# SAMA7G54D4G device description
Architecture: CORTEX-A7; Family: SAMA; Series: SAMA7G
Registers are 32-bit, read-write, reset 0x0 unless marked. A register's access mark holds for its fields unless they carry their own. Offsets are from the block's base; [hi:lo] are bit positions; {n}, {i} and the like mark numbered series.

## DDR3PHY — DDR SDRAM PHY Utility Block Lite
Instances: DDRPUBL 0xE3804000
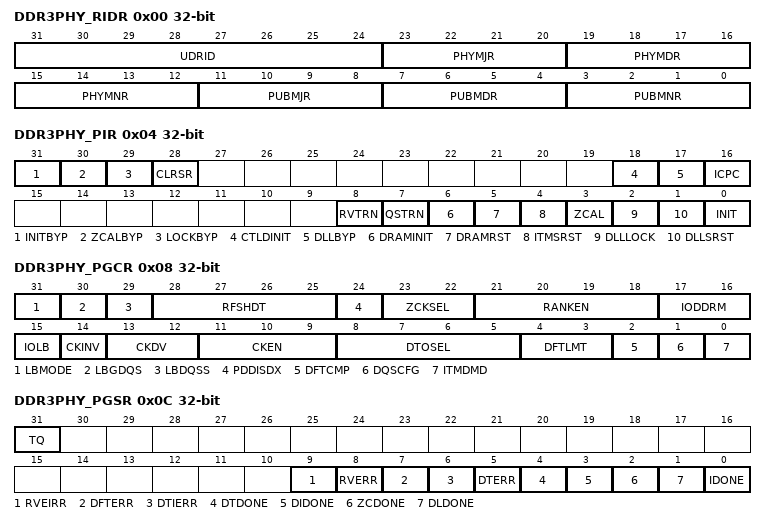
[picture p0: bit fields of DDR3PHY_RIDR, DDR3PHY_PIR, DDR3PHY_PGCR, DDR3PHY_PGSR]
0x00 DDR3PHY_RIDR ro reset not defined — Revision Identification Register
  [31:24] UDRID — User-Defined Revision ID: General purpose revision identification set by the user.
  [23:20] PHYMJR — PHY Major Revision: Indicates major revision of the PHY such addition of the features that make the new version not compatible with previous versions.
  [19:16] PHYMDR — PHY Moderate Revision: Indicates moderate revision of the PHY such as addition of new features. Normally the new version is still compatible with previous versions.
  [15:12] PHYMNR — PHY Minor Revision: Indicates minor update of the PHY such as bug fixes. Normally no new features are included.
  [11:8] PUBMJR — PUB Major Revision: Indicates major revision of the PUB such addition of the features that make the new version not compatible with previous versions.
  [7:4] PUBMDR — PUB Moderate Revision: Indicates moderate revision of the PUB such as addition of new features. Normally the new version is still compatible with previous versions.
  [3:0] PUBMNR — PUB Minor Revision: Indicates minor update of the PUB such as bug fixes. Normally no new features are included.
0x04 DDR3PHY_PIR reset not defined — PHY Initialization Register
  [31] INITBYP — Initialization Bypass: Bypasses or stops, if set, all initialization routines currently running, including PHY initialization, DRAM initialization, and PHY training.
  [30] ZCALBYP — Impedance Calibration Bypass: Bypasses or stops, if set, impedance calibration of all ZQ control blocks that automatically triggers after reset. Impedance calibration may be triggered manually using INIT and ZCAL bits of the PIR register. This bit is self-clearing.
  [29] LOCKBYP — DLL Lock Bypass: Bypasses or stops, if set, the waiting of DLLs to lock. DLL lock wait is automatically triggers after reset. DLL lock wait may be triggered manually using INIT and DLLLOCK bits of the PIR register. This bit is self-clearing.
  [28] CLRSR — Clear Status Registers
  [18] CTLDINIT — Controller DRAM Initialization: Indicates if set that DRAM initialization will be performed by the controller. Otherwise if not set it indicates that DRAM initialization will be performed using the built-in initialization sequence or using software through the configuration port.
  [17] DLLBYP — DLL Bypass: A setting of 1 on this bit will put all PHY DLLs in bypass mode. A bypassed DLL is also powered down (disabled).
  [16] ICPC — Initialization Complete Pin Configuration: Specifies how the DFI 2.1 initialization complete output pin should be used to indicate the status of initialization.
  [8] RVTRN — Read DQS gate training (QSTRN) and RV training (RVTRN) should normally be run together. It is expected RVTRN is normally be set whenever PIR.QSTRN is set.
  [7] QSTRN — Read DQS Training: Executes a PUBL training routine to determine the optimum position of the read data DQS strobe for maximum system timing margins.
  [6] DRAMINIT — DRAM Initialization: Executes the DRAM initialization sequence.
  [5] DRAMRST — DRAM Reset (DDR3 Only): Issues a reset to the DRAM (by driving the DRAM reset pin low) and wait 200us. This can be triggered in isolation or with the full DRAM initialization (DRAMINIT). For the latter case, the reset is issued and 200us is waited before starting the full initialization sequence.
  [4] ITMSRST — Interface Timing Module Soft Reset: Soft resets the interface timing modules for the data and data strobes, i.e., it asserts the ITM soft reset (srstb) signal.
  [3] ZCAL — Impedance Calibrate: Performs PHY impedance calibration.
  [2] DLLLOCK — DLL Lock: Waits for the PHY DLLs to lock.
  [1] DLLSRST — DLL Soft Rest: Soft resets all PHY DLLs by driving the DLL soft reset pin.
  [0] INIT — Initialization Trigger: A write of '1' to this bit triggers the DDR system initialization, including PHY initialization, DRAM initialization, and PHY training. The exact initialization steps to be executes are specified in bits 1 to 6 of this register. A bit setting of 1 means the step will be executed as part of the initialization sequence, while a setting of '0' means the step will be bypassed. The initialization trigger bit is self-clearing.
0x08 DDR3PHY_PGCR reset not defined — PHY General Configuration Register
  [31] LBMODE — Loopback Mode: Indicates if set that the PHY/PUB is in loopback mode
  [30] LBGDQS — Loopback DQS Gating: Selects the DQS gating mode that should be used when the PHY is in loopback mode, including BIST loopback mode.
  [29] LBDQSS — Loopback DQS Shift: Selects how the read DQS is shifted during loopback to ensure that the read DQS is centered into the read data eye.
  [28:25] RFSHDT — Refresh During Training: A non-zero value specifies that a burst of refreshes equal to the number specified in this field should be sent to the SDRAM after training each rank except the last rank.
  [24] PDDISDX — Power Down Disabled Byte: Indicates if set that the DLL and I/Os of a disabled byte should be powered down.
  [23:22] ZCKSEL — Impedance Clock Divider Select: Impedance Clock Divider Select: Selects the divide ratio for the clock used by the impedance control logic. The source clock for the divider is the configuration port clock signal (cfg_clk or pclk), depending on which configuration port type used (see 'Impedance Calibration' ).
  [21:18] RANKEN — Rank Enable: Specifies the ranks that are enabled for data-training. Bit 0 controls rank 0, bit 1 controls rank 1, bit 2 controls rank 2, and bit 3 controls rank 3. Setting the bit to '1' enables the rank, and setting it to '0' disables the rank.
  [17:16] IODDRM — I/O DDR Mode (D3F I/O Only): Selects the DDR mode for the I/Os.
  [15] IOLB — I/O Loop-Back Select: Selects where inside the I/O the loop-back of signals happens. Not applicable to D3A I/Os.
  [14] CKINV — CK Invert: Specifies if set that CK/CK# should be inverted. Otherwise CK/CK# toggles with normal polarity.
  [13:12] CKDV — CK Disable Value: Specifies the static value that should be driven on CK/CK# pair(s) when the pair(s) is disabled. CKDV[0] specifies the value for CK and CKDV[1] specifies the value for CK#.
  [11:9] CKEN — CK Enable: Controls whether the CK going to the SDRAM is enabled (toggling) or disabled (static value defined by CKDV). One bit for each of the three CK pairs.
  [8:5] DTOSEL — Digital Test Output Select: Selects the PHY digital test output that should be driven onto PHY digital test output (phy_dto) pin.
  [4:3] DFTLMT — DQS Drift Limit: Specifies the expected limit of drift on read data strobes. A drift of this value or greater is reported as a drift error through the host port error flag.
  [2] DFTCMP — DQS Drift Compensation: Enables or disables DQS drift compensation.
  [1] DQSCFG — DQS Gating Configuration: Selects one of the two DQS gating schemes.
  [0] ITMDMD — ITM DDR Mode: Selects whether ITMS uses DQS and DQS# or it only uses DQS.
0x0C DDR3PHY_PGSR ro reset not defined — PHY General Status Register
  [31] TQ — Temperature Output (LPDDR Only): Connected to the DRAM TQ pin which is defined to go high when the LPDDR device temperature equals to or exceeds 85oC, otherwise it is low.
  [9] RVEIRR — Read Valid Training Intermittent Error: If set, indicates that there was an intermittent error during read valid training, such as a pass was followed by a fail then followed by another pass.
  [8] RVERR — Read Valid Training Error: If set, indicates that a valid read valid placement could not be found during read valid training.
  [7] DFTERR — DQS Drift Error: If set, indicates that at least one of the read data strobes has drifted by more than or equal to the drift limit set in the PHY General Configuration Register (PGCR).
  [6] DTIERR — DQS Gate Training Intermittent Error: If set, indicates that there was an intermittent error during DQS gate training, such as a pass was followed by a fail then followed by another pass.
  [5] DTERR — DQS GateTraining Error: If set, indicates that a valid DQS gating window could not be found during DQS gate training.
  [4] DTDONE — Data Training Done: Indicates, if set, that the PHY has finished doing data training.
  [3] DIDONE — DRAM Initialization Done: Indicates if set that DRAM initialization has completed.
  [2] ZCDONE — Impedance Calibration Done: Indicates if set that impedance calibration has completed.
  [1] DLDONE — DLL Lock Done: Indicates if set that DLL locking has completed.
  [0] IDONE — Initialization Done: Indicates if set that the DDR system initialization has completed. This bit is set after all the selected initialization routines in PIR register have completed.
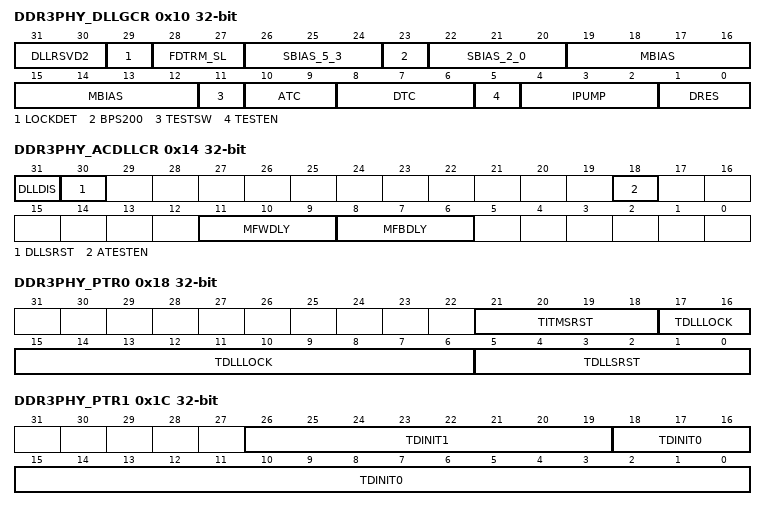
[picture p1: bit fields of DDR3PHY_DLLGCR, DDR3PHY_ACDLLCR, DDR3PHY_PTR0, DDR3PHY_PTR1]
0x10 DDR3PHY_DLLGCR reset not defined — DLL General Control Register
  [31:30] DLLRSVD2 — DLL Reserved Control: This bit is connected to the DLL control bus and is reserved for future use.
  [29] LOCKDET — Master lock detector enable.
  [28:27] FDTRM_SL — Slave Bypass Fixed Delay Trim
  [26:24] SBIAS_5_3 — Slave Bias Trim: Used to trim the bias for the slave DLL.
  [23] BPS200 — Bypass Mode Frequency Range
  [22:20] SBIAS_2_0 — Slave Bias Trim: Used to trim the bias for the slave DLL.
  [19:12] MBIAS — Master Bias Trim: Used to trim the bias for the master DLL.
  [11] TESTSW — Test Switch: Selects the test signals of either the master DLL, set to 0, or the slave DLL, set to 1.
  [10:9] ATC — Analog Test Control: Selects the analog signal to be output on the DLL analog test output (test_out_a) when TESTEN is high (Output is Vss when TESTEN is low). The test output either comes from the master DLL or the slave DLL, depending on the setting of the test switch (TESTSW). Both master DLL and slave DLL output similar analog test signals.
  [8:6] DTC — Digital Test Control: Selects the digital signal to be output on the DLL digital test output (test_out_d[1]) when TESTEN is high (Output is '0' when TESTEN is low).
  [5] TESTEN — Test Enable: Enables digital and analog test outputs selected by DTC and ATC respectively.
  [4:2] IPUMP — Charge Pump Current Trim: Used to trim charge pump current.
  [1:0] DRES — Delta Resistor Trim: Used to trim reference current versus resistor value variation.
0x14 DDR3PHY_ACDLLCR reset not defined — AC DLL Control Register
  [31] DLLDIS — DLL Disable: A disabled DLL is bypassed. Default ('0') is DLL enabled.
  [30] DLLSRST — DLL Soft Rest: Soft resets the AC DLL by driving the DLL soft reset pin.
  [18] ATESTEN — Analog Test Enable: Enables the analog test signal to be output on the DLL analog test output (test_out_a). The DLL analog test output is tri-stated when this bit is '0'.
  [11:9] MFWDLY — Master Feed-Forward Delay Trim: Used to trim the delay in the master DLL feedforward path.
  [8:6] MFBDLY — Master Feed-Back Delay Trim: Used to trim the delay in the master DLL feedback path.
0x18 DDR3PHY_PTR0 reset not defined — PHY Timing Register 0
  [21:18] TITMSRST — ITM Soft Reset Time: Number of configuration clock cycles that the ITM soft reset pin must remain asserted when the soft reset is applied to the ITMs. This must correspond to a value that is equal to or more than 8 controller clock cycles. Default value corresponds to 8 controller clock cycles.
  [17:6] TDLLLOCK — DLL Lock Time: Number of configuration clock cycles for the DLL to stabilize and lock, i.e. number of clock cycles from when the DLL reset pin is de-asserted to when the DLL has locked and is ready for use. Refer to the PHY databook for the DLL lock time. Default value corresponds to 5.12us at 533MHz.
  [5:0] TDLLSRST — DLL Soft Reset Time: Number of configuration clock cycles that the DLL soft reset pin must remain asserted when the soft reset is triggered through the PHY
0x1C DDR3PHY_PTR1 reset not defined — PHY Timing Register 1
  [26:19] TDINIT1 — DRAM Initialization Time 1.
  [18:0] TDINIT0 — DRAM Initialization Time 0.
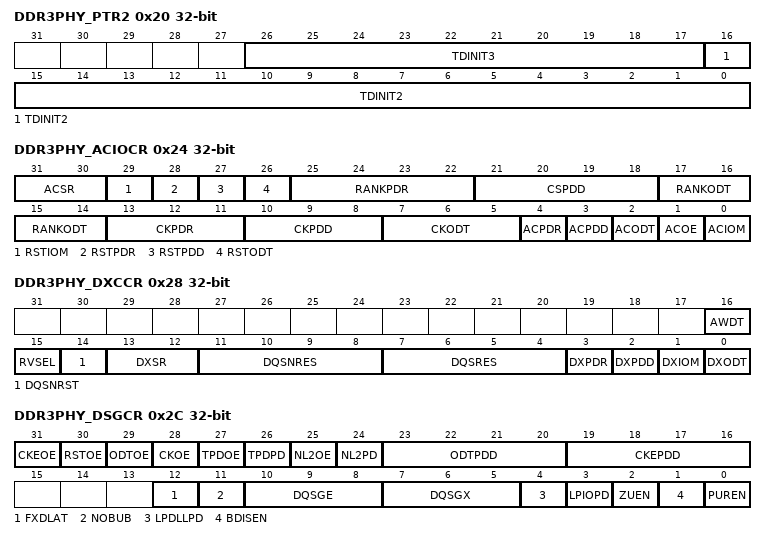
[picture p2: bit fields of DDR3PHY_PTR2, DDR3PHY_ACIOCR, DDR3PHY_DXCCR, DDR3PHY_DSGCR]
0x20 DDR3PHY_PTR2 reset not defined — PHY Timing Register 2
  [26:17] TDINIT3 — DRAM Initialization Time 3.
  [16:0] TDINIT2 — DRAM Initialization Time 2.
0x24 DDR3PHY_ACIOCR reset not defined — AC I/O Configuration Register
  [31:30] ACSR — Address/Command Slew Rate (D3F I/O Only): Selects slew rate of the I/O for all address and command pins, as well as the optional DIMM PAR_IN pin and LPDDR TPD pin.
  [29] RSTIOM — SDRAM Reset I/O Mode: Selects SSTL mode (when set to 0) or CMOS mode (when set to 1) of the I/O for SDRAM Reset.
  [28] RSTPDR — SDRAM Reset Power Down Receiver: Powers down, when set, the input receiver on the I/O for SDRAM RST# pin.
  [27] RSTPDD — SDRAM Reset Power Down Driver: Powers down, when set, the output driver on the I/O for SDRAM RST# pin.
  [26] RSTODT — SDRAM Reset On-Die Termination: Enables, when set, the on-die termination on the I/O for SDRAM RST# pin.
  [25:22] RANKPDR — Rank Power Down Receiver: Powers down, when set, the input receiver on the I/O
  [21:18] CSPDD — CS# Power Down Driver: Powers down, when set, the output driver on the I/O for CS#[3:0] pins. PDD[0] controls the power down for CS#[0], PDD[1] controls the power down for CS#[1], and so on. CKE and ODT driver power down is controlled by DSGCR register.
  [17:14] RANKODT — Rank On-Die Termination: Enables, when set, the on-die termination on the I/O for CKE[3:0], ODT[3:0], and CS#[3:0] pins. RANKODT[0] controls the on-die termination for CKE[0], ODT[0], and CS#[0], RANKODT[1] controls the on-die termination for CKE[1], ODT[1], and CS#[1], and so on.
  [13:11] CKPDR — CK Power Down Receiver: Powers down, when set, the input receiver on the I/O for CK[0], CK[1], and CK[2] pins, respectively.
  [10:8] CKPDD — CK Power Down Driver: Powers down, when set, the output driver on the I/O for CK[0], CK[1], and CK[2] pins, respectively.
  [7:5] CKODT — CK On-Die Termination: Enables, when set, the on-die termination on the I/O for CK[0], CK[1], and CK[2] pins, respectively.
  [4] ACPDR — AC Power Down Receiver: Powers down, when set, the input receiver on the I/O for RAS#, CAS#, WE#, BA[2:0], and A[15:0] pins, as well as the optional DIMM PAR_IN pin and LPDDR TPD pin.
  [3] ACPDD — AC Power Down Driver: Powers down, when set, the output driver on the I/O for RAS#, CAS#, WE#, BA[2:0], and A[15:0] pins, as well as the optional DIMM PAR_IN pin.
  [2] ACODT — Address/Command On-Die Termination: Enables, when set, the on-die termination on the I/O for RAS#, CAS#, WE#, BA[2:0], and A[15:0] pins, as well as the optional DIMM PAR_IN pin and LPDDR TPD pin.
  [1] ACOE — Address/Command Output Enable: Enables, when set, the output driver on the I/O for all address and command pins, as well as the optional DIMM PAR_IN pin and LPDDR TPD pin.
  [0] ACIOM — Address/Command I/O Mode: Selects SSTL mode (when set to 0) or CMOS mode (when set to 1) of the I/O for all address and command pins, as well as the optional DIMM PAR_IN pin and LPDDR TPD pin.
0x28 DDR3PHY_DXCCR reset not defined — DATX8 I/O Configuration Register
  [16] AWDT — Active Window Data Train: Indicates if set that data training (DQS gate training and read valid training) should be performed with active DQS gate window. This is just for debug purposes. The default is to perform training with passive windowing.
  [15] RVSEL — ITMD Read Valid Select: Selects the scheme used for ITMD read valid.
  [14] DQSNRST — DQS# Reset: Indicates, if set, that the ITMS of DQS# should always be put in reset such that its output enable is always '1' and its data output is always '0'. This is done by driving the oe_set_b and do_rst_b pins of this ITMS to '0' in order to force the unused DQS# PAD to a known state of '0' in applications that don't use DQS# such as in LPDDR mode.
  [13:12] DXSR — Data Slew Rate (D3F I/O Only): Selects slew rate of the I/O for DQ, DM, and DQS/DQS# pins of all DATX8 macros.
  [11:8] DQSNRES — DQS# Resistor: Selects the on-die pull-up/pull-down resistor for DQS# pins. Same encoding as DQSRES.
  [7:4] DQSRES — DQS Resistor: Selects the on-die pull-down/pull-up resistor for DQS pins.
  [3] DXPDR — Data Power Down Receiver: Powers down, when set, the input receiver on I/O for
  [2] DXPDD — Data Power Down Driver: Powers down, when set, the output driver on I/O for DQ, DM, and DQS/DQS# pins of all DATX8 macros. This bit is ORed with the PDD configuration bit of the individual DATX8
  [1] DXIOM — Data I/O Mode: Selects SSTL mode (when set to 0) or CMOS mode (when set to 1) of the I/O for DQ, DM, and DQS/DQS# pins of all DATX8 macros. This bit is ORed with the IOM configuration bit of the individual DATX8
  [0] DXODT — Data On-Die Termination: Enables, when set, the on-die termination on the I/O for DQ, DM, and DQS/DQS# pins of all DATX8 macros. This bit is ORed with the ODT configuration bit of the individual DATX8
0x2C DDR3PHY_DSGCR reset not defined — DFI Configuration Register
  [31] CKEOE — SDRAM CKE Output Enable: Enables, when set, the output driver on the I/O for SDRAM CKE pins.
  [30] RSTOE — SDRAM Reset Output Enable: Enables, when set, the output driver on the I/O for SDRAM RST# pin.
  [29] ODTOE — SDRAM ODT Output Enable: Enables, when set, the output driver on the I/O for SDRAM ODT pins.
  [28] CKOE — SDRAM CK Output Enable: Enables, when set, the output driver on the I/O for SDRAM CK/CK# pins.
  [27] TPDOE — SDRAM TPD Output Enable (LPDDR Only): Enables, when set, the output driver on the I/O for SDRAM TPD pin.
  [26] TPDPD — SDRAM TPD Power Down Driver (LPDDR Only): Powers down, when set, the output driver on the I/O for SDRAM TPD pin. Note that the power down of the receiver on the I/O for SDRAM TPD pin is controlled by ACIOCR[ACPDR] register bit.
  [25] NL2OE — Non-LPDDR2/LPDDR3 Output Enable: Enables, when set, the output driver on the I/O for non-LPDDR2/LPDDR3 (ODT, RAS#, CAS#, WE#, and BA) pins. This may be used when a chip that is designed for both LPDDR2/LPDDR3 and other DDR modes is being used in LPDDR2/LPDDR3 mode. For these pins, the I/O output enable signal (OE) is an AND of this bit and the respective output enable bit in ACIOCR or DSGCR registers.
  [24] NL2PD — Non-LPDDR2/LPDDR3 Power Down: Powers down, when set, the output driver and the input receiver on the I/O for non-LPDDR2/LPDDR3 (ODT, RAS#, CAS#, WE#,
  [23:20] ODTPDD — ODT Power Down Driver: Powers down, when set, the output driver on the I/O for ODT[3:0] pins. ODTPDD[0] controls the power down for ODT[0], ODTPDD[1] controls the power down for ODT[1], and so on.
  [19:16] CKEPDD — CKE Power Down Driver: Powers down, when set, the output driver on the I/O for CKE[3:0] pins. CKEPDD[0] controls the power down for CKE[0], CKEPDD[1] controls the power down for CKE[1], and so on.
  [12] FXDLAT — Fixed Latency: Specified whether all reads should be returned to the controller with a fixed read latency. Enabling fixed read latency increases the read latency.
  [11] NOBUB — No Bubbles: Specified whether reads should be returned to the controller with no bubbles. Enabling no-bubble reads increases the read latency.
  [10:8] DQSGE — DQS Gate Early: Specifies the number of clock cycles for which the DQS gating must be enabled earlier than its normal position. Only applicable when using PDQSR I/O cell, passive DQS gating and no drift compensation. This field is recommended to be set to zero for all DDR types other than
  [7:5] DQSGX — DQS Gate Extension: Specifies the number of clock cycles for which the DQS gating must be extended beyond the normal burst length width. Only applicable when using PDQSR I/O cell, passive DQS gating and no drift compensation. This field is recommended to be set to zero for all DDR types other than
  [4] LPDLLPD — Low Power DLL Power Down: Specifies if set that the PHY should respond to the DFI low power opportunity request and power down the DLL of the PHY if the wakeup time request satisfies the DLL lock time.
  [3] LPIOPD — Low Power I/O Power Down: Specifies if set that the PHY should respond to the DFI low power opportunity request and power down the I/Os of the PHY.
  [2] ZUEN — Impedance Update Enable: Specifies if set that the PHY should perform impedance calibration (update) whenever there is a controller initiated DFI update request.
  [1] BDISEN — Byte Disable Enable: Specifies if set that the PHY should respond to DFI byte disable request. Otherwise the byte disable from the DFI is ignored in which case bytes can only be disabled using the DXnGCR register.
  [0] PUREN — PHY Update Request Enable: Specifies if set, that the PHY should issue PHYinitiated DFI update request when there is DQS drift of more than 3/4 of a clock cycle within one continuous (back-to-back) read burst. By default the PHY issues PHYinitiated update requests and the controller should respond otherwise the PHY may return erroneous values. The option to disable it is provided only for silicon evaluation and testing.
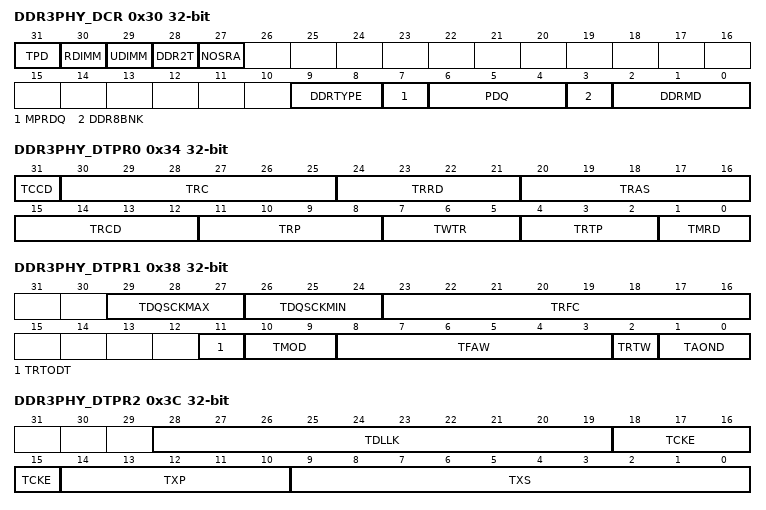
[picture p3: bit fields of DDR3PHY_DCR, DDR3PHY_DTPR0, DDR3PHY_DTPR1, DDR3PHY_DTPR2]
0x30 DDR3PHY_DCR reset not defined — DRAM Configuration Register
  [31] TPD — Test Power Down (LPDDR Only): If set will place the DRAM in deep power down mode.
  [30] RDIMM — Registered DIMM: Indicates if set that a registered DIMM is used. In this case, the PUB increases the SDRAM write and read latencies (WL/RL) by 1. This only applies to PUB internal SDRAM transactions. Transactions generated by the controller must make its own adjustments to WL/RL when using a registered DIMM.
  [29] UDIMM — Un-buffered DIMM Address Mirroring: Indicates if set that there is address mirroring on the second rank of an un-buffered DIMM (the rank connected to CS#[1]). In this case, the PUB re-scrambles the bank and address when sending mode register commands to the second rank. This only applies to PUB internal SDRAM transactions. Transactions generated by the controller must make its own adjustments when using an un-buffered DIMM. DCR[NOSRA] must be set if address mirroring is enabled.
  [28] DDR2T — DDR 2T Timing: Indicates if set that 2T timing should be used by PUB internally generated SDRAM transactions.
  [27] NOSRA — No Simultaneous Rank Access: Specifies if set that simultaneous rank access on the same clock cycle is not allowed. This means that multiple chip select signals should not be asserted at the same time. This may be required on some DIMM systems.
  [9:8] DDRTYPE — DDR Type: Selects the DDR type for the specified LPDDR mode.
  [7] MPRDQ — Multi-Purpose Register (MPR) DQ (DDR3 Only): Specifies the value that is driven on non-primary DQ pins during MPR reads.
  [6:4] PDQ — Primary DQ (DDR3 Only): Specifies the DQ pin in a byte that is designated as a primary pin for Multi-Purpose Register (MPR) reads. Valid values are 0 to 7 for DQ[0] to DQ[7], respectively.
  [3] DDR8BNK — DDR 8-Bank: Indicates if set that the SDRAM used has 8 banks. tRPA = tRP+1 and tFAW are used for 8-bank DRAMs, other tRPA = tRP and no tFAW is used. Note that
  [2:0] DDRMD — DDR Mode: SDRAM DDR mode.
0x34 DDR3PHY_DTPR0 reset not defined — SDRAM Timing Parameters Register 0
  [31] TCCD — Read to read and write to write command delay.
  [30:25] TRC — Activate to activate command delay (same bank). Valid values are 2 to 42.
  [24:21] TRRD — Activate to activate command delay (different banks). Valid values are 1 to 8.
  [20:16] TRAS — Activate to precharge command delay. Valid values are 2 to 31.
  [15:12] TRCD — Activate to read or write delay. Minimum time from when an activate command is issued to when a read or write to the activated row can be issued. Valid values are 2 to 11.
  [11:8] TRP — Precharge command period: The minimum time between a precharge command and any other command. Note that the Controller automatically derives tRPA for 8bank DDR2 devices by adding 1 to tRP. Valid values are 2 to 11.
  [7:5] TWTR — Internal write to read command delay. Valid values are 1 to 6.
  [4:2] TRTP — Internal read to precharge command delay. Valid values are 2 to 6. Note that even though RTP does not apply to JEDEC DDR devices, this parameter must still be set to a minimum value of 2 for DDR because the Controller always uses the DDR2 equation, AL + BL/2 + max(RTP,2) - 2, to compute the read to precharge timing (which is BL/2 for JEDEC DDR).
  [1:0] TMRD — Load mode cycle time: The minimum time between a load mode register command and any other command. For DDR3 this is the minimum time between two load mode register commands. Valid values for DDR2 are 2 to 3. For DDR3, the value used for tMRD is 4 plus the value programmed in these bits, i.e. tMRD value for DDR3 ranges from 4 to 7. For LPDDR3, the value used for tMRD is 8 plus the value programmed in these bits.
0x38 DDR3PHY_DTPR1 reset not defined — SDRAM Timing Parameters Register 1
  [29:27] TDQSCKMAX — Maximum DQS output access time from CK/CK# (LPDDR2 only). This value is used for implementing read-to-write spacing. Valid values are 1 to 7.
  [26:24] TDQSCKMIN — DQS output access time from CK/CK# (LPDDR2/3 only). This value is used for computing the read latency. Valid values are 0 to 7. This value is derived from the corresponding parameter in the SDRAM datasheet divided by the clock cycle time without rounding up. The fractional remainder is automatically adjusted for by data training in quarter clock cycle units. If data training is not performed then this fractional remainder must be converted to quarter clock cycle units and the gating registers (DXnDQSTR) adjusted accordingly.
  [23:16] TRFC — Refresh-to-Refresh: Indicates the minimum time, in clock cycles, between two refresh commands or between a refresh and an active command. This is derived from the minimum refresh interval from the datasheet, tRFC(min), divided by the clock cycle time. The default number of clock cycles is for the largest JEDEC tRFC(min parameter value supported.
  [11] TRTODT — Read to ODT delay (DDR3 only). Specifies whether ODT can be enabled immediately after the read post-amble or one clock delay has to be added.
  [10:9] TMOD — Load mode update delay (DDR3 only). The minimum time between a load mode register command and a non-load mode register command.
  [8:3] TFAW — 4-bank activate period. No more than 4-bank activate commands may be issued in a given tFAW period. Only applies to 8-bank devices. Valid values are 2 to 31.
  [2] TRTW — Read to Write command delay.
  [1:0] TAOND — ODT turn-on/turn-off delays (DDR2 only). The delays are in clock cycles. Valid values are: 00 = 2/2.5
0x3C DDR3PHY_DTPR2 reset not defined — SDRAM Timing Parameters Register 2
  [28:19] TDLLK — DLL locking time. Valid values are 2 to 1023.
  [18:15] TCKE — CKE minimum pulse width. Also specifies the minimum time that the SDRAM must remain in power down or self refresh mode. For DDR3 this parameter must be set to the value of tCKESR which is usually bigger than the value of tCKE. Valid values are 2 to 15.
  [14:10] TXP — Power down exit delay. The minimum time between a power down exit command and any other command. This parameter must be set to the maximum of the various minimum power down exit delay parameters specified in the SDRAM datasheet, i.e. max(tXP, tXARD, tXARDS) for DDR2 and max(tXP, tXPDLL) for DDR3. Valid values are 2 to 31.
  [9:0] TXS — Self refresh exit delay. The minimum time between a self refresh exit command and any other command. This parameter must be set to the maximum of the various minimum self refresh exit delay parameters specified in the SDRAM datasheet, i.e. max(tXSNR, tXSRD) for DDR2 and max(tXS, tXSDLL) for DDR3. Valid values are 2 to 1023.
0x40 DDR3PHY_MR0 reset not defined — Mode Register
0x44 DDR3PHY_MR1 reset not defined — Extended Mode Register
0x48 DDR3PHY_MR2 reset not defined — Extended Mode Register 2
0x4C DDR3PHY_MR3 reset not defined — Extended Mode Register 3
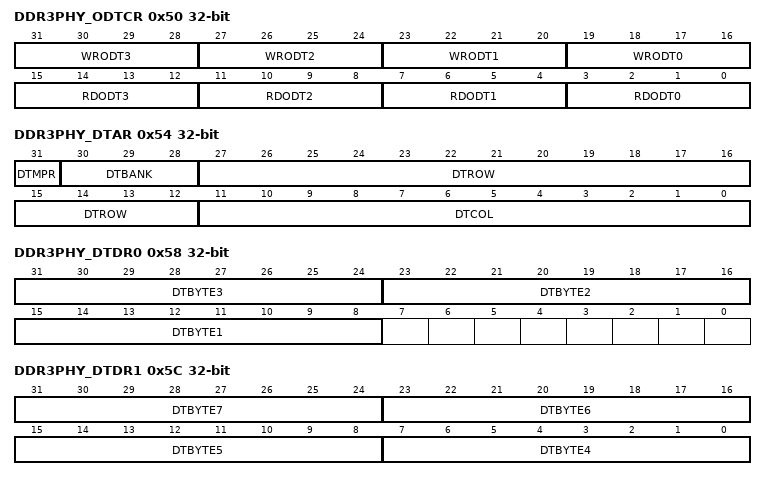
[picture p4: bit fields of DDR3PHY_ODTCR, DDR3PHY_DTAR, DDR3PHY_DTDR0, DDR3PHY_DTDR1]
0x50 DDR3PHY_ODTCR reset not defined — ODT Configuration Register
  [31:28] WRODT3
  [27:24] WRODT2
  [23:20] WRODT1
  [19:16] WRODT0 — Write ODT: Specifies whether ODT should be enabled ('1') or disabled ('0') on each of the up to four ranks when a write command is sent to rank n. WRODT0,
  [4n+3:4n] RDODT{n} (n=0..3)
0x54 DDR3PHY_DTAR reset not defined — Data Training Address Register
  [31] DTMPR — Data Training Using MPR (DDR3 Only): Specifies, if set, that data-training should use the SDRAM Multi-Purpose Register (MPR) register. Otherwise data-training is performed by first writing to some locations in the SDRAM and then reading them back.
  [30:28] DTBANK — Data Training Bank Address: Selects the SDRAM bank address to be used during data training.
  [27:12] DTROW — Data Training Row Address: Selects the SDRAM row address to be used during data training.
  [11:0] DTCOL — Data Training Column Address: Selects the SDRAM column address to be used during data training. The lower four bits of this address must always be "0000".
0x58 DDR3PHY_DTDR0 reset not defined — Data Training Data Register 0
  [31:24] DTBYTE3 — Data Training Data: The first 4 bytes of data used during data training. This same data byte is used for each Byte Lane. Default sequence is a walking 1 while toggling data every data cycle.
  [23:16] DTBYTE2 — Data Training Data: The first 4 bytes of data used during data training. This same data byte is used for each Byte Lane. Default sequence is a walking 1 while toggling data every data cycle.
  [15:8] DTBYTE1 — Data Training Data: The first 4 bytes of data used during data training. This same data byte is used for each Byte Lane. Default sequence is a walking 1 while toggling data every data cycle.
0x5C DDR3PHY_DTDR1 reset not defined — Data Training Data Register 1
  [8n-25:8n-32] DTBYTE{n} (n=4..7) — Data Training Data: The second 4 bytes of data used during data training. This same data byte is used for each Byte Lane. Default sequence is a walking 1 while toggling data every data cycle.
0x60 DDR3PHY_DTPSL ro reset not defined — Data Training Phase shift Log
0x64 DDR3PHY_ACODLY reset not defined — Data Training AC Ouput delay
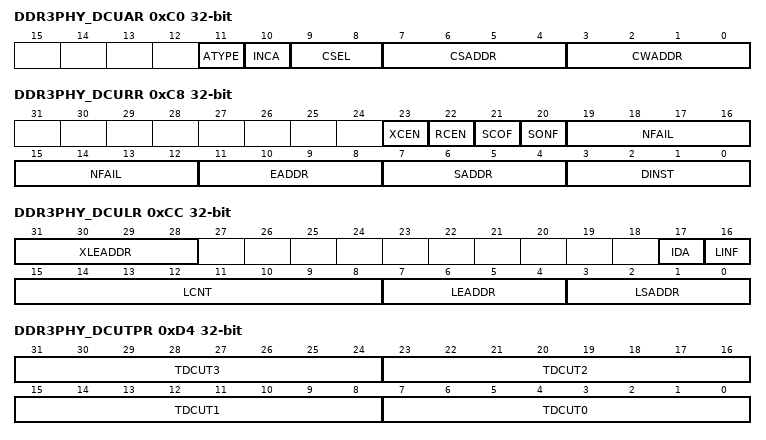
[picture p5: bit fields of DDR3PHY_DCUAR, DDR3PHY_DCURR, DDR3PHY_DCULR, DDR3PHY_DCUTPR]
0xC0 DDR3PHY_DCUAR reset not defined — DCU Address Register
  [11] ATYPE — Access Type: Specifies the type of access to be performed using this address. Valid values are: 0 = Write access
  [10] INCA — Increment Address: Specifies, if set, that the cache address specified in WADDR and SADDR should be automatically incremented after each access of the cache. The increment happens in such a way that all the slices of a selected word are first accessed before going to the next word.
  [9:8] CSEL — Cache Select: Selects the cache to be accessed.
  [7:4] CSADDR — Cache Slice Address: Address of the cache slice to be accessed.
  [3:0] CWADDR — Cache Word Address: Address of the cache word to be accessed.
0xC4 DDR3PHY_DCUDR reset not defined — DCU Data Register
  [31:0] CDATA — Cache Data: Data to be written to or read from a cache. This data corresponds to the cache word slice specified by the DCU Address Register.
0xC8 DDR3PHY_DCURR reset not defined — DCU Run Register
  [23] XCEN — Expected Compare Enable: Indicates if set that read data coming back from the SDRAM should be should be compared with the expected data.
  [22] RCEN — Read Capture Enable: Indicates if set that read data coming back from the SDRAM should be captured into the read data cache.
  [21] SCOF — Stop Capture On Full: Specifies if set that the capture of read data should stop when the capture cache is full.
  [20] SONF — Stop On Nth Fail: Specifies if set that the execution of commands and the capture of read data should stop when there are N read data failures. The number of failures is specified by NFAIL. Otherwise commands execute until the end of the program or until manually stopped using a STOP command.
  [19:12] NFAIL — Number of Failures: Specifies the number of failures after which the execution of commands and the capture of read data should stop if SONF bit of this register is set. Execution of commands and the capture of read data will stop after (NFAIL+1) failures if SONF is set.
  [11:8] EADDR — End Address: Cache word address where the execution of command should end.
  [7:4] SADDR — Start Address: Cache word address where the execution of commands should begin.
  [3:0] DINST — DCU Instruction: Selects the DCU command to be executed.
0xCC DDR3PHY_DCULR reset not defined — DCU Loop Register
  [31:28] XLEADDR — Expected Data Loop End Address: The last expected data cache word address that contains valid expected data. Expected data should looped between 0 and this address.
  [17] IDA — Increment DRAM Address: Indicates if set that DRAM addresses should be incremented every time a DRAM read/write command inside the loop is executed.
  [16] LINF — Loop Infinite: Indicates if set that the loop should be executed indefinitely until stopped by the STOP command. Otherwise the loop is execute LCNT times.
  [15:8] LCNT — Loop Count: The number of times that the loop should be executed if LINF is not set.
  [7:4] LEADDR — Loop End Address: Command cache word address where the loop should end.
  [3:0] LSADDR — Loop Start Address: Command cache word address where the loop should start.
0xD0 DDR3PHY_DCUGCR reset not defined — DCU General Configuration Register
  [15:0] RCSW — Read Capture Start Word: The capture and compare of read data should start after Nth word. For example setting this value to 12 will skip the first 12 read data.
0xD4 DDR3PHY_DCUTPR reset not defined — DCU Timing Parameter Register
  [8n+7:8n] TDCUT{n} (n=0..3) — DCU Generic Timing Parameter {n}.
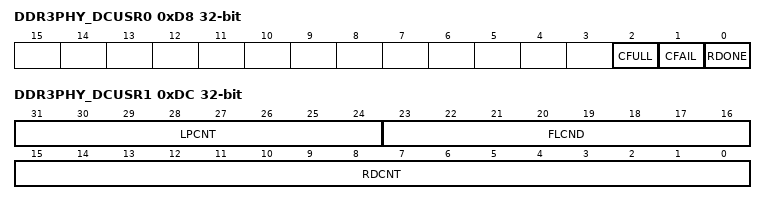
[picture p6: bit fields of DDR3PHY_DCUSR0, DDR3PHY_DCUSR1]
0xD8 DDR3PHY_DCUSR0 reset not defined — DCU Status-0 Register
  [2] CFULL — Capture Full: Indicates if set that the capture cache is full.
  [1] CFAIL — Capture Fail: Indicates if set that at least one read data word has failed.
  [0] RDONE — Run Done: Indicates if set that the DCU has finished executing the commands in the command cache. This bit is also set to indicate that a STOP command has successfully been executed and command execution has stopped.
0xDC DDR3PHY_DCUSR1 reset not defined — DCU Status-1 Register
  [31:24] LPCNT — Loop Count: Indicates the value of the loop count. This is useful when the program has stooped because of failures to assess how many reads were executed before first fail.
  [23:16] FLCND — Fail Count: Number of read words that have failed.
  [15:0] RDCNT — Read Count: Number of read words returned from the SDRAM.
0x100 DDR3PHY_BISTRR reset not defined — BIST Run Register
0x104 DDR3PHY_BISTMSKR0 reset not defined — BIST Mask 0 Register
0x108 DDR3PHY_BISTMSKR1 reset not defined — BIST Mask 1 Register
0x10C DDR3PHY_BISTWCR reset not defined — BIST Word Count Register
0x110 DDR3PHY_BISTLSR reset not defined — BIST LFSR Seed Register
{0x114+4i} DDR3PHY_BISTAR{i} reset not defined (i=0..2) — BIST Address {i} Register
0x120 DDR3PHY_BISTUDPR reset not defined — BIST User Data Pattern Register
0x124 DDR3PHY_BISTGSR reset not defined — BIST General Status Register
0x128 DDR3PHY_BISTWER reset not defined — BIST Word Error Register
{0x12C+4i} DDR3PHY_BISTBER{i} reset not defined (i=0..2) — BIST Bit Error {i} Register
0x138 DDR3PHY_BISTWCSR reset not defined — BIST Word Count Status Register
0x13C DDR3PHY_BISTFWR0 reset not defined — BIST Fail Word 0 Register
0x140 DDR3PHY_BISTFWR1 reset not defined — BIST Fail Word 1 Register
0x178 DDR3PHY_GPR0 reset not defined — General Purpose Register 0
0x17C DDR3PHY_GPR1 reset not defined — General Purpose Register 1
{0x180+0x10*i} DDR3PHY_ZQ{i}CR0 reset not defined (i=0..3) — ZQ Impedence Control Register 0
{0x184+0x10*i} DDR3PHY_ZQ{i}CR1 reset not defined (i=0..3) — ZQ Impedence Control Register 1
{0x188+0x10*i} DDR3PHY_ZQ{i}SR0 ro reset not defined (i=0..3) — ZQ Impedence Control Status Register 0
{0x18C+0x10*i} DDR3PHY_ZQ{i}SR1 ro reset not defined (i=0..3) — ZQ Impedence Control Status Register 1
{0x1C0+0x40*i} DDR3PHY_DX{i}GCR reset not defined (i=0..8) — DATX8 General Configuration Register
{0x1C4+0x40*i} DDR3PHY_DX{i}GSR0 ro reset not defined (i=0..8) — DATX8 General Status Register 0
{0x1C8+0x40*i} DDR3PHY_DX{i}GSR1 ro reset not defined (i=0..8) — DATX8 General Status Register 1
{0x1CC+0x40*i} DDR3PHY_DX{i}DLLCR reset not defined (i=0..8) — DATX8 DLL Control Register
{0x1D0+0x40*i} DDR3PHY_DX{i}DQTR reset not defined (i=0..8) — DATX8 DQ Timing Register
{0x1D4+0x40*i} DDR3PHY_DX{i}DQSTR reset not defined (i=0..8) — DATX8 DQS Timing Register
{0x1D8+0x40*i} DDR3PHY_DX{i}DQIDLY reset not defined (i=0..8) — DATX8 DQ Input Delay
{0x1DC+0x40*i} DDR3PHY_DX{i}DQODLY reset not defined (i=0..8) — DATX8 DQ Output Delay
{0x1E0+0x40*i} DDR3PHY_DX{i}DQSIDLY reset not defined (i=0..8) — DATX8 DQS Input Delay
{0x1E4+0x40*i} DDR3PHY_DX{i}DQSODLY reset not defined (i=0..8) — DATX8 DQS Output Delay

## Notices in the file
Copyright (c) 2020 Microchip Technology Inc.
SPDX-License-Identifier: Apache-2.0
Licensed under the Apache License, Version 2.0 (the "License");
you may not use this file except in compliance with the License.
You may obtain a copy of the License at
http://www.apache.org/licenses/LICENSE-2.0
Unless required by applicable law or agreed to in writing, software
distributed under the License is distributed on an "AS IS" BASIS,
WITHOUT WARRANTIES OR CONDITIONS OF ANY KIND, either express or implied.
See the License for the specific language governing permissions and
limitations under the License.
